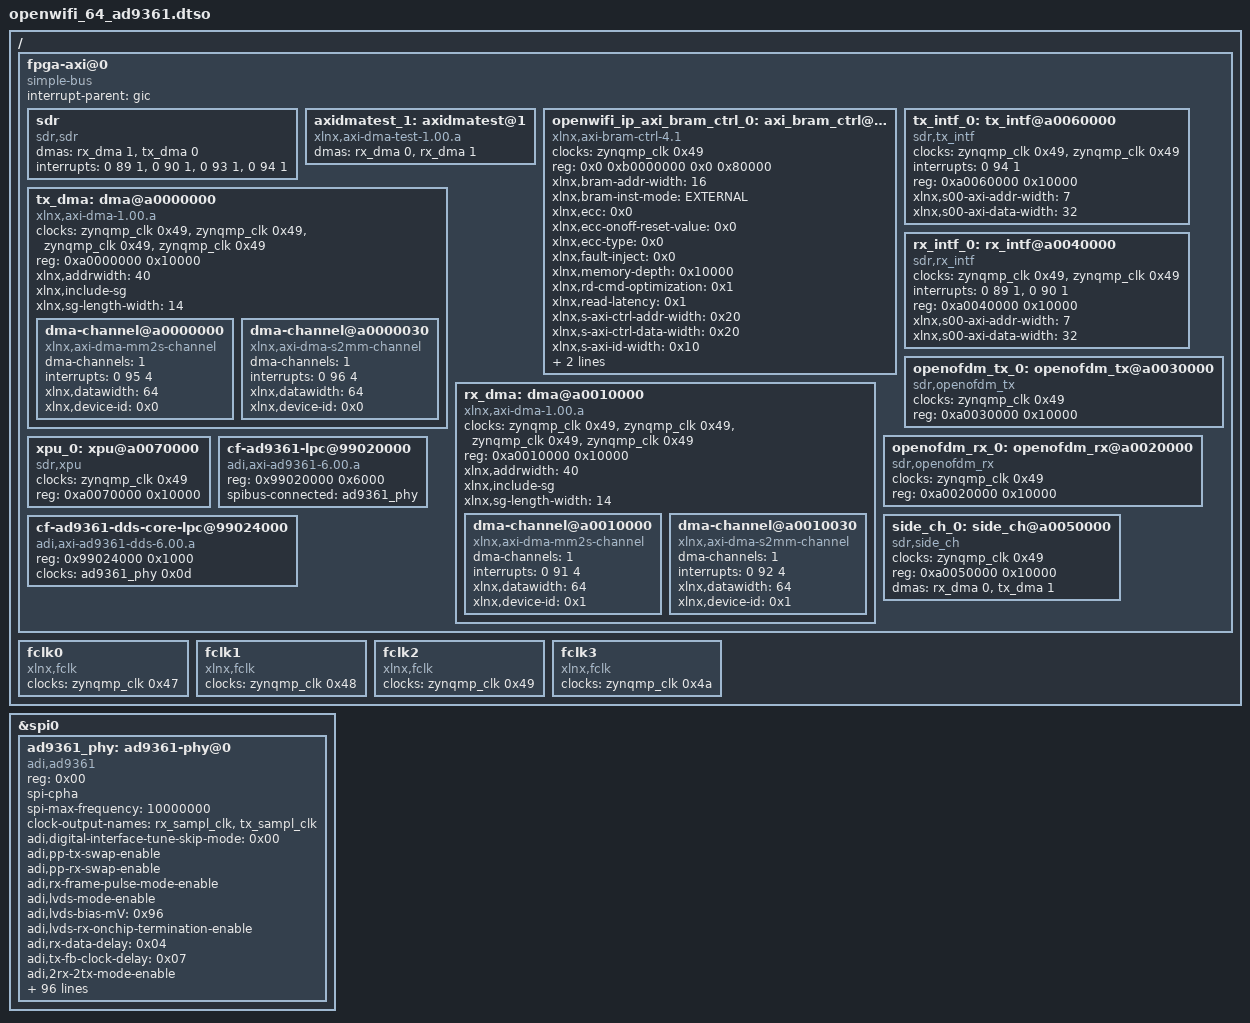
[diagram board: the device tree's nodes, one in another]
/dts-v1/;
/plugin/;

/ {
    // Insert axi devices in fpga
    fragment@0{
        target-path = "/";
        __overlay__{
            fpga-axi@0 {
                interrupt-parent = <&gic>;
                compatible = "simple-bus";
                #address-cells = <1>;
                #size-cells = <1>;
                ranges = <0x00 0x00 0x00 0xffffffff>;

                sdr: sdr {
                    compatible ="sdr,sdr";
                    dmas = <&rx_dma 1
                            &tx_dma 0>;
                    dma-names = "rx_dma_s2mm", "tx_dma_mm2s";
                    interrupt-names = "not_valid_anymore", "rx_pkt_intr", "tx_itrpt_useless", "tx_itrpt";
                    interrupts = <0 89 1>, <0 90 1>, <0 93 1>, <0 94 1>;
                } ;

                axidmatest_1: axidmatest@1 {
                    compatible ="xlnx,axi-dma-test-1.00.a";
                    dmas = <&rx_dma 0
                            &rx_dma 1>;
                    dma-names = "axidma0", "axidma1";
                } ;

                openwifi_ip_axi_bram_ctrl_0: axi_bram_ctrl@b0000000 {
                    clock-names = "s_axi_aclk";
                    clocks = <&zynqmp_clk 0x49>;
                    compatible = "xlnx,axi-bram-ctrl-4.1";
                    reg = <0x0 0xb0000000 0x0 0x80000>;
                    xlnx,bram-addr-width = <16>;
                    xlnx,bram-inst-mode = "EXTERNAL";
                    xlnx,ecc = <0x0>;
                    xlnx,ecc-onoff-reset-value = <0x0>;
                    xlnx,ecc-type = <0x0>;
                    xlnx,fault-inject = <0x0>;
                    xlnx,memory-depth = <0x10000>;
                    xlnx,rd-cmd-optimization = <0x1>;
                    xlnx,read-latency = <0x1>;
                    xlnx,s-axi-ctrl-addr-width = <0x20>;
                    xlnx,s-axi-ctrl-data-width = <0x20>;
                    xlnx,s-axi-id-width = <0x10>;
                    xlnx,s-axi-supports-narrow-burst = <0x1>;
                    xlnx,single-port-bram = <0x1>;
                };

                tx_dma: dma@a0000000 {
                    #dma-cells = <1>;
                    clock-names = "s_axi_lite_aclk", "m_axi_sg_aclk", "m_axi_mm2s_aclk", "m_axi_s2mm_aclk";
                    clocks = <&zynqmp_clk 0x49>, <&zynqmp_clk 0x49>, <&zynqmp_clk 0x49>, <&zynqmp_clk 0x49>;
                    compatible = "xlnx,axi-dma-1.00.a";
                    reg = <0xa0000000 0x10000>;
                    xlnx,addrwidth = <40>;
                    xlnx,include-sg ;
                    xlnx,sg-length-width = <14>;
                    dma-channel@a0000000 {
                        compatible = "xlnx,axi-dma-mm2s-channel";
                        dma-channels = <1>;
                        interrupts = <0 95 4>;
                        xlnx,datawidth = <64>;
                        xlnx,device-id = <0x0>;
                    };
                    dma-channel@a0000030 {
                        compatible = "xlnx,axi-dma-s2mm-channel";
                        dma-channels = <1>;
                        interrupts = <0 96 4>;
                        xlnx,datawidth = <64>;
                        xlnx,device-id = <0x0>;
                    };
                };

                rx_dma: dma@a0010000 {
                    #dma-cells = <1>;
                    clock-names = "s_axi_lite_aclk", "m_axi_sg_aclk", "m_axi_mm2s_aclk", "m_axi_s2mm_aclk";
                    clocks = <&zynqmp_clk 0x49>, <&zynqmp_clk 0x49>, <&zynqmp_clk 0x49>, <&zynqmp_clk 0x49>;
                    compatible = "xlnx,axi-dma-1.00.a";
                    //dma-coherent ;
                    reg = <0xa0010000 0x10000>;
                    xlnx,addrwidth = <40>;
                    xlnx,include-sg ;
                    xlnx,sg-length-width = <14>;
                    dma-channel@a0010000 {
                        compatible = "xlnx,axi-dma-mm2s-channel";
                        dma-channels = <1>;
                        interrupts = <0 91 4>;
                        xlnx,datawidth = <64>;
                        xlnx,device-id = <0x1>;
                    };
                    dma-channel@a0010030 {
                        compatible = "xlnx,axi-dma-s2mm-channel";
                        dma-channels = <1>;
                        interrupts = <0 92 4>;
                        xlnx,datawidth = <64>;
                        xlnx,device-id = <0x1>;
                    };
                };

                tx_intf_0: tx_intf@a0060000 {
                    clock-names = "s00_axi_aclk", "s00_axis_aclk";//, "s01_axis_aclk", "m00_axis_aclk";
                    clocks = <&zynqmp_clk 0x49>, <&zynqmp_clk 0x49>;//, <&zynqmp_clk 0x49>, <&zynqmp_clk 0x49>;
                    compatible = "sdr,tx_intf";
                    interrupt-names = "tx_itrpt";
                    interrupts = <0 94 1>;
                    reg = <0xa0060000 0x10000>;
                    xlnx,s00-axi-addr-width = <7>;
                    xlnx,s00-axi-data-width = <32>;
                };

                rx_intf_0: rx_intf@a0040000 {
                    clock-names = "s00_axi_aclk", "m00_axis_aclk";//, "s00_axis_aclk";
                    clocks = <&zynqmp_clk 0x49>, <&zynqmp_clk 0x49>;//, <&zynqmp_clk 0x49>;
                    compatible = "sdr,rx_intf";
                    interrupt-names = "not_valid_anymore", "rx_pkt_intr";
                    interrupts = <0 89 1>, <0 90 1>;
                    reg = <0xa0040000 0x10000>;
                    xlnx,s00-axi-addr-width = <7>;
                    xlnx,s00-axi-data-width = <32>;
                };

                openofdm_tx_0: openofdm_tx@a0030000 {
                    clock-names = "clk";
                    clocks = <&zynqmp_clk 0x49>;
                    compatible = "sdr,openofdm_tx";
                    reg = <0xa0030000 0x10000>;
                };

                openofdm_rx_0: openofdm_rx@a0020000 {
                    clock-names = "clk";
                    clocks = <&zynqmp_clk 0x49>;
                    compatible = "sdr,openofdm_rx";
                    reg = <0xa0020000 0x10000>;
                };

                xpu_0: xpu@a0070000 {
                    clock-names = "s00_axi_aclk";
                    clocks = <&zynqmp_clk 0x49>;
                    compatible = "sdr,xpu";
                    reg = <0xa0070000 0x10000>;
                };

                side_ch_0: side_ch@a0050000 {
                    clock-names = "s00_axi_aclk";
                    clocks = <&zynqmp_clk 0x49>;
                    compatible = "sdr,side_ch";
                    reg = <0xa0050000 0x10000>;
                    dmas = <&rx_dma 0
                            &tx_dma 1>;
                    dma-names = "rx_dma_mm2s", "tx_dma_s2mm";
                };

                cf-ad9361-lpc@99020000 {
                    compatible = "adi,axi-ad9361-6.00.a";
                    reg = <0x99020000 0x6000>;
                    // dmas = <0x3c 0x00>;
                    // dma-names = "rx";
                    spibus-connected = <&ad9361_phy>;
                };

                cf-ad9361-dds-core-lpc@99024000 {
                    compatible = "adi,axi-ad9361-dds-6.00.a";
                    reg = <0x99024000 0x1000>;
                    clocks = <&ad9361_phy 0x0d>;
                    clock-names = "sampl_clk";
                    // dmas = <0x3e 0x00>;
                    // dma-names = "tx";
                };

                // axi-sysid-0@85000000 {
                // 	compatible = "adi,axi-sysid-1.00.a";
                // 	reg = <0x85000000 0x10000>;
                // };
            };
        };
    };

    // Add FPGA fabric clocks
    fragment@1{
        target-path = "/";
        __overlay__{
        	fclk0: fclk0 {
        		status = "okay";
        		compatible = "xlnx,fclk";
        		clocks = <&zynqmp_clk 0x47>;
        	};

        	fclk1: fclk1 {
        		status = "okay";
        		compatible = "xlnx,fclk";
        		clocks = <&zynqmp_clk 0x48>;
        	};

        	fclk2: fclk2 {
        		status = "okay";
        		compatible = "xlnx,fclk";
        		clocks = <&zynqmp_clk 0x49>;
        	};

        	fclk3: fclk3 {
        		status = "okay";
        		compatible = "xlnx,fclk";
        		clocks = <&zynqmp_clk 0x4a>;
        	};
        };
    };

    // Insert AD9361 SPI device
    fragment@2{
        target = <&spi0>;
        __overlay__{
            ad9361_phy: ad9361-phy@0 {
                compatible = "adi,ad9361";
                reg = <0x00>;
                spi-cpha;
                spi-max-frequency = <10000000>;
                clock-names = "ad9361_ext_refclk";
                clock-output-names = "rx_sampl_clk", "tx_sampl_clk";
                #clock-cells = <1>;
                adi,digital-interface-tune-skip-mode = <0x00>;
                adi,pp-tx-swap-enable;
                adi,pp-rx-swap-enable;
                adi,rx-frame-pulse-mode-enable;
                adi,lvds-mode-enable;
                adi,lvds-bias-mV = <0x96>;
                adi,lvds-rx-onchip-termination-enable;
                adi,rx-data-delay = <0x04>;
                adi,tx-fb-clock-delay = <0x07>;
                adi,2rx-2tx-mode-enable;
                adi,frequency-division-duplex-mode-enable;
                adi,rx-rf-port-input-select = <0x00>;
                adi,tx-rf-port-input-select = <0x00>;
                adi,tx-attenuation-mdB = <0x2710>;
                adi,tx-lo-powerdown-managed-enable;
                adi,rf-rx-bandwidth-hz = <0x112a880>;
                adi,rf-tx-bandwidth-hz = <0x112a880>;
                adi,rx-synthesizer-frequency-hz = <0 2400000000>;
                adi,tx-synthesizer-frequency-hz = <0 2450000000>;
                adi,rx-path-clock-frequencies = <0x3a980000 0xea60000 0x7530000 0x3a98000 0x1d4c000 0x1d4c000>;
                adi,tx-path-clock-frequencies = <0x3a980000 0x7530000 0x7530000 0x3a98000 0x1d4c000 0x1d4c000>;
                adi,gc-rx1-mode = <0x02>;
                adi,gc-rx2-mode = <0x02>;
                adi,gc-adc-ovr-sample-size = <0x04>;
                adi,gc-adc-small-overload-thresh = <0x2f>;
                adi,gc-adc-large-overload-thresh = <0x3a>;
                adi,gc-lmt-overload-high-thresh = <0x320>;
                adi,gc-lmt-overload-low-thresh = <0x2c0>;
                adi,gc-dec-pow-measurement-duration = <0x2000>;
                adi,gc-low-power-thresh = <0x18>;
                adi,mgc-inc-gain-step = <0x02>;
                adi,mgc-dec-gain-step = <0x02>;
                adi,mgc-split-table-ctrl-inp-gain-mode = <0x00>;
                adi,agc-attack-delay-extra-margin-us = <0x01>;
                adi,agc-outer-thresh-high = <0x05>;
                adi,agc-outer-thresh-high-dec-steps = <0x02>;
                adi,agc-inner-thresh-high = <0x0a>;
                adi,agc-inner-thresh-high-dec-steps = <0x01>;
                adi,agc-inner-thresh-low = <0x0c>;
                adi,agc-inner-thresh-low-inc-steps = <0x01>;
                adi,agc-outer-thresh-low = <0x12>;
                adi,agc-outer-thresh-low-inc-steps = <0x02>;
                adi,agc-adc-small-overload-exceed-counter = <0x0a>;
                adi,agc-adc-large-overload-exceed-counter = <0x0a>;
                adi,agc-adc-large-overload-inc-steps = <0x07>;
                adi,agc-lmt-overload-large-exceed-counter = <0x0a>;
                adi,agc-lmt-overload-small-exceed-counter = <0x0a>;
                adi,agc-lmt-overload-large-inc-steps = <0x07>;
                adi,agc-gain-update-interval-us = <0x3e8>;
                adi,fagc-dec-pow-measurement-duration = <0x10>;
        adi,fagc-adc-large-overload-inc-steps = <0x07>;
                adi,fagc-lp-thresh-increment-steps = <0x01>;
                adi,fagc-lp-thresh-increment-time = <0x05>;
                adi,fagc-energy-lost-stronger-sig-gain-lock-exit-cnt = <0x08>;
        adi,fagc-dig-sat-ovrg-enable;
                adi,fagc-final-overrange-count = <0x03>;
                adi,fagc-gain-index-type-after-exit-rx-mode = <0x00>;
                adi,fagc-lmt-final-settling-steps = <0x01>;
                adi,fagc-lock-level = <0x0a>;
                adi,fagc-lock-level-gain-increase-upper-limit = <0x05>;
                adi,fagc-lock-level-lmt-gain-increase-enable;
                adi,fagc-lpf-final-settling-steps = <0x01>;
                adi,fagc-optimized-gain-offset = <0x05>;
                adi,fagc-power-measurement-duration-in-state5 = <0x10>;
                adi,fagc-rst-gla-engergy-lost-goto-optim-gain-enable;
                adi,fagc-rst-gla-engergy-lost-sig-thresh-below-ll = <0x0a>;
                adi,fagc-rst-gla-if-en-agc-pulled-high-mode = <0x00>;
                adi,fagc-rst-gla-large-adc-overload-enable;
                adi,fagc-rst-gla-large-lmt-overload-enable;
                adi,fagc-rst-gla-stronger-sig-thresh-above-ll = <0x0a>;
                adi,fagc-state-wait-time-ns = <0x104>;
                adi,fagc-use-last-lock-level-for-set-gain-enable;
                adi,rssi-restart-mode = <0x03>;
                adi,rssi-delay = <0x01>;
                adi,rssi-wait = <0x01>;
                adi,rssi-duration = <0x3e8>;
                adi,ctrl-outs-index = <0x00>;
                adi,ctrl-outs-enable-mask = <0xff>;
                adi,temp-sense-measurement-interval-ms = <0x3e8>;
                adi,temp-sense-offset-signed = <0xce>;
                adi,temp-sense-periodic-measurement-enable;
                adi,aux-dac-manual-mode-enable;
                adi,aux-dac1-default-value-mV = <0x00>;
                adi,aux-dac1-rx-delay-us = <0x00>;
                adi,aux-dac1-tx-delay-us = <0x00>;
                adi,aux-dac2-default-value-mV = <0x00>;
                adi,aux-dac2-rx-delay-us = <0x00>;
                adi,aux-dac2-tx-delay-us = <0x00>;
                en_agc-gpios = <&gpio 0x7a 0x00>;
                sync-gpios = <&gpio 0x7b 0x00>;
                reset-gpios = <&gpio 0x7c 0x00>;
                enable-gpios = <&gpio 0x7d 0x00>;
                txnrx-gpios = <&gpio 0x7e 0x00>;
            };
        };
    };

    // Enable SPI bus connecting to ad9361
    fragment@3{
        target = <&spi0>;
        __overlay__{
            status = "okay";
        };
    };
};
